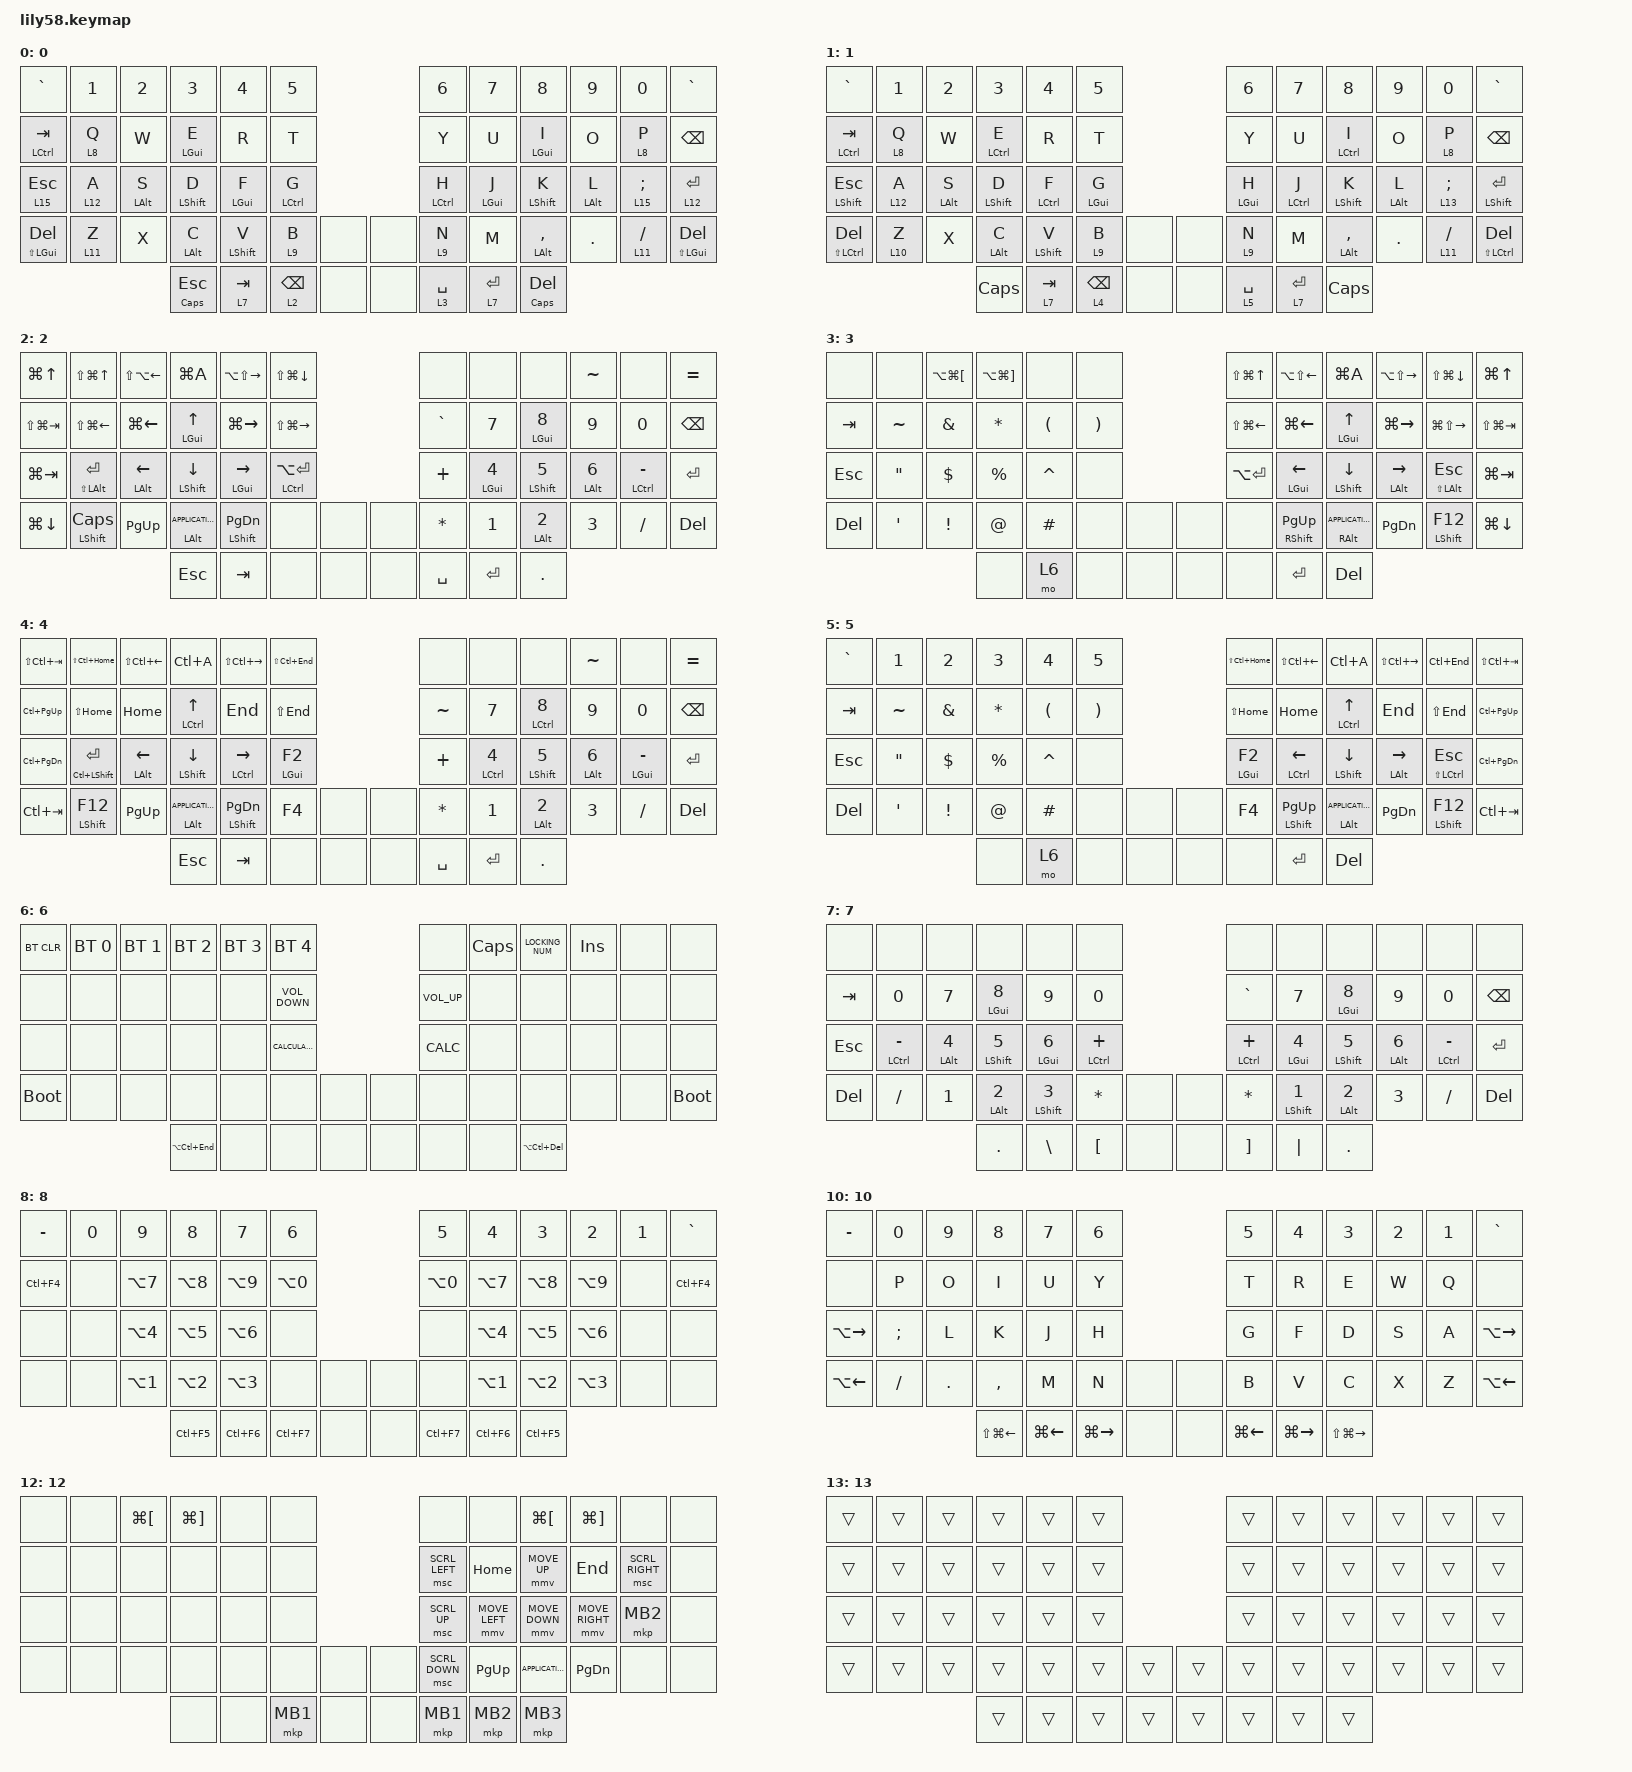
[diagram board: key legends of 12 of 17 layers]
/*
 * Copyright (c) 2020 The ZMK Contributors
 *
 * SPDX-License-Identifier: MIT
 */

#define ZMK_POINTING_DEFAULT_MOVE_VAL 900  // 기본 600
#define ZMK_POINTING_DEFAULT_SCRL_VAL 15    // 기본 10

#include <behaviors.dtsi>
#include <dt-bindings/zmk/bt.h>
#include <dt-bindings/zmk/keys.h>
#include <dt-bindings/zmk/pointing.h>

/ {
    combos {
        compatible = "zmk,combos";

        MOD_del {
            bindings = <&kp DELETE>;
            key-positions = <14 52>;
        };

        MOD_ent {
            bindings = <&kp ENTER>;
            key-positions = <15 52>;
            require-prior-idle-ms = <100>;
        };

        MOD_space {
            bindings = <&kp SPACE>;
            key-positions = <16 52>;
            require-prior-idle-ms = <100>;
        };

        MOD_BS {
            bindings = <&kp BACKSPACE>;
            key-positions = <55 19>;
            require-prior-idle-ms = <100>;
        };

        MOD_TA {
            bindings = <&kp TAB>;
            key-positions = <55 20>;
            require-prior-idle-ms = <100>;
        };

        MOD_esc {
            bindings = <&kp ESCAPE>;
            key-positions = <55 21>;
            require-prior-idle-ms = <100>;
        };

        Q_ {
            bindings = <&kp LS(Q)>;
            key-positions = <26 25>;
            layers = <0 1>;
        };

        W_ {
            bindings = <&kp LS(W)>;
            key-positions = <14 15>;
            layers = <0>;
        };

        E_ {
            bindings = <&kp LS(E)>;
            key-positions = <27 26>;
            layers = <0>;
        };

        R_ {
            bindings = <&kp LS(R)>;
            key-positions = <15 16>;
            layers = <0>;
        };

        T_ {
            bindings = <&kp LS(T)>;
            key-positions = <27 28>;
            layers = <0>;
        };

        P_ {
            bindings = <&kp LS(P)>;
            key-positions = <34 33>;
            layers = <0>;
        };

        B_ {
            bindings = <&kp B>;
            key-positions = <32 33>;
            layers = <0>;
        };

        paste0 {
            bindings = <&kp LG(V)>;
            key-positions = <52 28>;
            require-prior-idle-ms = <100>;
            layers = <0>;
        };

        copy0 {
            bindings = <&kp LG(C)>;
            key-positions = <27 52>;
            require-prior-idle-ms = <100>;
            layers = <0>;
        };

        cut0 {
            bindings = <&kp LG(X)>;
            key-positions = <26 52>;
            require-prior-idle-ms = <100>;
            layers = <0>;
        };

        AltTab0 {
            bindings = <&kp LG(TAB)>;
            key-positions = <25 52>;
            require-prior-idle-ms = <100>;
            layers = <0>;
        };

        paste1 {
            bindings = <&kp LC(V)>;
            key-positions = <52 28>;
            layers = <1>;
        };

        copy1 {
            bindings = <&kp LC(C)>;
            key-positions = <27 52>;
            layers = <1>;
        };

        cut1 {
            bindings = <&kp LC(X)>;
            key-positions = <26 52>;
            layers = <1>;
        };

        AltTab1 {
            bindings = <&kp LC(TAB)>;
            key-positions = <25 52>;
            layers = <1>;
        };

        Lan_LH0 {
            bindings = <&kp LC(SPACE)>;
            key-positions = <52 40>;
            layers = <0>;
        };

        Lan_RH0 {
            bindings = <&kp LC(SPACE)>;
            key-positions = <31 32>;
            layers = <0>;
        };

        Lan_LH1 {
            bindings = <&kp RALT>;
            key-positions = <52 40>;
            layers = <1>;
        };

        Lan_RH1 {
            bindings = <&kp RALT>;
            key-positions = <31 32>;
            layers = <1>;
        };

        Hanja_LH {
            bindings = <&kp RCTRL>;
            key-positions = <52 39>;
            layers = <0 1>;
        };

        Hanja_RH {
            bindings = <&kp RCTRL>;
            key-positions = <45 46>;
            layers = <0 1>;
        };

        question_LH {
            bindings = <&kp QUESTION>;
            key-positions = <37 38>;
            layers = <0 1>;
        };

        question_RH {
            bindings = <&kp QUESTION>;
            key-positions = <47 48>;
            layers = <0 1>;
        };

        click_L {
            bindings = <&mkp MB1>;
            key-positions = <29 52>;
            layers = <0 1>;
        };

        toWIN {
            bindings = <&to 0>;
            key-positions = <52 51 50>;
        };

        toMAC {
            bindings = <&mo 0>;
            key-positions = <55 56 57>;
        };
    };

    behaviors {
        hmMT: hmMT {
            compatible = "zmk,behavior-hold-tap";
            label = "HMMT";
            bindings = <&kp>, <&kp>;

            #binding-cells = <2>;
            tapping-term-ms = <250>;
            flavor = "tap-preferred";
        };

        hmLT: hmLT {
            compatible = "zmk,behavior-hold-tap";
            label = "HMLT";
            bindings = <&mo>, <&kp>;

            #binding-cells = <2>;
            tapping-term-ms = <250>;
            flavor = "tap-preferred";
        };
    };

    macros {
        new_macro0: new_macro0 {
            compatible = "zmk,behavior-macro";
            #binding-cells = <0>;
            bindings = <&kp LS(LG(RIGHT)) &kp LA(SPACE) &kp X>;
            label = "NEW_MACRO0";
        };

        new_macro1: new_macro1 {
            compatible = "zmk,behavior-macro";
            #binding-cells = <0>;
            bindings = <&kp LA(SPACE) &kp C>;
            label = "NEW_MACRO1";
        };

        new_macro2: new_macro2 {
            compatible = "zmk,behavior-macro";
            #binding-cells = <0>;
            bindings = <&kp LA(SPACE) &kp X>;
            label = "NEW_MACRO2";
        };

        new_macro3: new_macro3 {
            compatible = "zmk,behavior-macro";
            #binding-cells = <0>;
            bindings = <&kp LA(SPACE) &kp N>;
            label = "NEW_MACRO3";
        };

        new_macro4: new_macro4 {
            compatible = "zmk,behavior-macro";
            #binding-cells = <0>;
            bindings = <&kp LA(D) &kp LC(C) &kp LA(TAB)>;
            label = "NEW_MACRO4";
        };

        new_macro5: new_macro5 {
            compatible = "zmk,behavior-macro";
            #binding-cells = <0>;
            bindings = <&kp LA(D) &kp LC(V) &kp ENTER>;
            label = "NEW_MACRO5";
        };

        new_macro6: new_macro6 {
            compatible = "zmk,behavior-macro";
            #binding-cells = <0>;
            bindings = <&kp LEFT_PARENTHESIS &kp RIGHT_PARENTHESIS &kp LEFT_ARROW>;
            label = "NEW_MACRO6";
        };

        new_macro7: new_macro7 {
            compatible = "zmk,behavior-macro";
            #binding-cells = <0>;
            bindings = <&kp LESS_THAN &kp GREATER_THAN &kp LEFT_ARROW>;
            label = "NEW_MACRO7";
        };

        new_macro8: new_macro8 {
            compatible = "zmk,behavior-macro";
            #binding-cells = <0>;
            bindings = <&kp LEFT_BRACKET &kp RIGHT_BRACKET &kp LEFT_ARROW>;
            label = "NEW_MACRO8";
        };

        new_macro9: new_macro9 {
            compatible = "zmk,behavior-macro";
            #binding-cells = <0>;
            bindings = <&kp SPACE &kp SPACE &kp SPACE &kp SPACE>;
            label = "NEW_MACRO9";
        };

        new_macro10: new_macro10 {
            compatible = "zmk,behavior-macro";
            #binding-cells = <0>;
            bindings = <&kp N1 &kp N0>;
            label = "NEW_MACRO10";
        };

        new_macro11: new_macro11 {
            compatible = "zmk,behavior-macro";
            #binding-cells = <0>;
            bindings = <&kp N1 &kp N1>;
            label = "NEW_MACRO11";
        };

        new_macro12: new_macro12 {
            compatible = "zmk,behavior-macro";
            #binding-cells = <0>;
            bindings = <&kp N1 &kp N2>;
            label = "NEW_MACRO12";
        };

        new_macro13: new_macro13 {
            compatible = "zmk,behavior-macro";
            #binding-cells = <0>;
            bindings = <&kp N1 &kp NUMBER_3>;
            label = "NEW_MACRO13";
        };

        new_macro14: new_macro14 {
            compatible = "zmk,behavior-macro";
            #binding-cells = <0>;
            bindings = <&none>;
            label = "NEW_MACRO14";
        };

        new_macro15: new_macro15 {
            compatible = "zmk,behavior-macro";
            #binding-cells = <0>;
            bindings = <&none>;
            label = "NEW_MACRO15";
        };

        new_macro16: new_macro16 {
            compatible = "zmk,behavior-macro";
            #binding-cells = <0>;
            bindings =
                <&macro_press>,
                <&macro_tap>,
                <&macro_tap>,
                <&macro_tap>,
                <&macro_release>;

            label = "NEW_MACRO16";
        };

        new_macro17: new_macro17 {
            compatible = "zmk,behavior-macro";
            #binding-cells = <0>;
            bindings =
                <&macro_press>,
                <&macro_tap>,
                <&macro_tap>,
                <&macro_tap>,
                <&macro_release>;

            label = "NEW_MACRO17";
        };

        new_macro18: new_macro18 {
            compatible = "zmk,behavior-macro";
            #binding-cells = <0>;
            bindings = <&kp D &kp K &kp S &kp S &kp U &kp D &kp G &kp K &kp T &kp P &kp D &kp Y &kp TILDE>;
            label = "NEW_MACRO18";
        };

        new_macro19: new_macro19 {
            compatible = "zmk,behavior-macro";
            #binding-cells = <0>;
            bindings = <&kp R &kp K &kp A &kp T &kp K &kp G &kp K &kp Q &kp S &kp L &kp E &kp K &kp DOT>;
            label = "NEW_MACRO19";
        };

        new_macro20: new_macro20 {
            compatible = "zmk,behavior-macro";
            #binding-cells = <0>;
            bindings = <&none>;
            label = "NEW_MACRO20";
        };

        new_macro21: new_macro21 {
            compatible = "zmk,behavior-macro";
            #binding-cells = <0>;
            bindings = <&none>;
            label = "NEW_MACRO21";
        };

        new_macro22: new_macro22 {
            compatible = "zmk,behavior-macro";
            #binding-cells = <0>;
            bindings = <&none>;
            label = "NEW_MACRO22";
        };

        new_macro23: new_macro23 {
            compatible = "zmk,behavior-macro";
            #binding-cells = <0>;
            bindings = <&none>;
            label = "NEW_MACRO23";
        };

        new_macro31: new_macro31 {
            compatible = "zmk,behavior-macro";
            #binding-cells = <0>;
            bindings =
                <&macro_press>,
                <&macro_tap>,
                <&macro_tap>,
                <&macro_tap>,
                <&macro_release>;

            label = "NEW_MACRO31";
        };

        new_macro32: new_macro32 {
            compatible = "zmk,behavior-macro";
            #binding-cells = <0>;
            bindings =
                <&macro_press>,
                <&macro_tap>,
                <&macro_tap>,
                <&macro_tap>,
                <&macro_release>;

            label = "NEW_MACRO32";
        };

        new_macro33: new_macro33 {
            compatible = "zmk,behavior-macro";
            #binding-cells = <0>;
            bindings =
                <&macro_press>,
                <&macro_tap>,
                <&macro_tap>,
                <&macro_tap>,
                <&macro_release>;

            label = "NEW_MACRO33";
        };

        new_macro34: new_macro34 {
            compatible = "zmk,behavior-macro";
            #binding-cells = <0>;
            bindings =
                <&macro_press>,
                <&macro_tap>,
                <&macro_tap>,
                <&macro_tap>,
                <&macro_release>;

            label = "NEW_MACRO34";
        };

        new_macro35: new_macro35 {
            compatible = "zmk,behavior-macro";
            #binding-cells = <0>;
            bindings =
                <&macro_press>,
                <&macro_tap>,
                <&macro_tap>,
                <&macro_tap>,
                <&macro_release>;

            label = "NEW_MACRO35";
        };

        new_macro36: new_macro36 {
            compatible = "zmk,behavior-macro";
            #binding-cells = <0>;
            bindings =
                <&macro_press>,
                <&macro_tap>,
                <&macro_tap>,
                <&macro_tap>,
                <&macro_release>;

            label = "NEW_MACRO36";
        };

        new_macro37: new_macro37 {
            compatible = "zmk,behavior-macro";
            #binding-cells = <0>;
            bindings =
                <&macro_press>,
                <&macro_tap>,
                <&macro_tap>,
                <&macro_tap>,
                <&macro_release>;

            label = "NEW_MACRO37";
        };

        new_macro38: new_macro38 {
            compatible = "zmk,behavior-macro";
            #binding-cells = <0>;
            bindings =
                <&macro_press>,
                <&macro_tap>,
                <&macro_tap>,
                <&macro_tap>,
                <&macro_release>;

            label = "NEW_MACRO38";
        };

        new_macro39: new_macro39 {
            compatible = "zmk,behavior-macro";
            #binding-cells = <0>;
            bindings =
                <&macro_press>,
                <&macro_tap>,
                <&macro_tap>,
                <&macro_tap>,
                <&macro_release>;

            label = "NEW_MACRO39";
        };

        new_macro40: new_macro40 {
            compatible = "zmk,behavior-macro";
            #binding-cells = <0>;
            bindings =
                <&macro_press>,
                <&macro_tap>,
                <&macro_tap>,
                <&macro_tap>,
                <&macro_release>;

            label = "NEW_MACRO40";
        };

        new_macro41: new_macro41 {
            compatible = "zmk,behavior-macro";
            #binding-cells = <0>;
            bindings =
                <&macro_press>,
                <&macro_tap>,
                <&macro_tap>,
                <&macro_tap>,
                <&macro_release>;

            label = "NEW_MACRO41";
        };

        new_macro42: new_macro42 {
            compatible = "zmk,behavior-macro";
            #binding-cells = <0>;
            bindings =
                <&macro_press>,
                <&macro_tap>,
                <&macro_tap>,
                <&macro_tap>,
                <&macro_release>;

            label = "NEW_MACRO42";
        };

        new_macro43: new_macro43 {
            compatible = "zmk,behavior-macro";
            #binding-cells = <0>;
            bindings =
                <&macro_press>,
                <&macro_tap>,
                <&macro_tap>,
                <&macro_tap>,
                <&macro_release>;

            label = "NEW_MACRO43";
        };

        new_macro44: new_macro44 {
            compatible = "zmk,behavior-macro";
            #binding-cells = <0>;
            bindings =
                <&macro_press>,
                <&macro_tap>,
                <&macro_tap>,
                <&macro_tap>,
                <&macro_release>;

            label = "NEW_MACRO44";
        };

        new_macro45: new_macro45 {
            compatible = "zmk,behavior-macro";
            #binding-cells = <0>;
            bindings =
                <&macro_press>,
                <&macro_tap>,
                <&macro_tap>,
                <&macro_tap>,
                <&macro_release>;

            label = "NEW_MACRO45";
        };

        new_macro46: new_macro46 {
            compatible = "zmk,behavior-macro";
            #binding-cells = <0>;
            bindings =
                <&macro_press>,
                <&macro_tap>,
                <&macro_tap>,
                <&macro_tap>,
                <&macro_release>;

            label = "NEW_MACRO46";
        };

        new_macro47: new_macro47 {
            compatible = "zmk,behavior-macro";
            #binding-cells = <0>;
            bindings =
                <&macro_press>,
                <&macro_tap>,
                <&macro_tap>,
                <&macro_tap>,
                <&macro_release>;

            label = "NEW_MACRO47";
        };

        new_macro48: new_macro48 {
            compatible = "zmk,behavior-macro";
            #binding-cells = <0>;
            bindings =
                <&macro_press>,
                <&macro_tap>,
                <&macro_tap>,
                <&macro_tap>,
                <&macro_release>;

            label = "NEW_MACRO48";
        };

        new_macro49: new_macro49 {
            compatible = "zmk,behavior-macro";
            #binding-cells = <0>;
            bindings =
                <&macro_press>,
                <&macro_tap>,
                <&macro_tap>,
                <&macro_tap>,
                <&macro_release>;

            label = "NEW_MACRO49";
        };

        new_macro50: new_macro50 {
            compatible = "zmk,behavior-macro";
            #binding-cells = <0>;
            bindings =
                <&macro_press>,
                <&macro_tap>,
                <&macro_tap>,
                <&macro_tap>,
                <&macro_release>;

            label = "NEW_MACRO50";
        };

        new_macro51: new_macro51 {
            compatible = "zmk,behavior-macro";
            #binding-cells = <0>;
            bindings =
                <&macro_press>,
                <&macro_tap>,
                <&macro_tap>,
                <&macro_tap>,
                <&macro_release>;

            label = "NEW_MACRO51";
        };

        new_macro52: new_macro52 {
            compatible = "zmk,behavior-macro";
            #binding-cells = <0>;
            bindings =
                <&macro_press>,
                <&macro_tap>,
                <&macro_tap>,
                <&macro_tap>,
                <&macro_release>;

            label = "NEW_MACRO52";
        };

        new_macro53: new_macro53 {
            compatible = "zmk,behavior-macro";
            #binding-cells = <0>;
            bindings =
                <&macro_press>,
                <&macro_tap>,
                <&macro_tap>,
                <&macro_tap>,
                <&macro_release>;

            label = "NEW_MACRO53";
        };

        new_macro54: new_macro54 {
            compatible = "zmk,behavior-macro";
            #binding-cells = <0>;
            bindings =
                <&macro_press>,
                <&macro_tap>,
                <&macro_tap>,
                <&macro_tap>,
                <&macro_release>;

            label = "NEW_MACRO54";
        };

        new_macro55: new_macro55 {
            compatible = "zmk,behavior-macro";
            #binding-cells = <0>;
            bindings =
                <&macro_press>,
                <&macro_tap>,
                <&macro_tap>,
                <&macro_tap>,
                <&macro_release>;

            label = "NEW_MACRO55";
        };

        new_macro56: new_macro56 {
            compatible = "zmk,behavior-macro";
            #binding-cells = <0>;
            bindings =
                <&macro_press>,
                <&macro_tap>,
                <&macro_tap>,
                <&macro_tap>,
                <&macro_release>;

            label = "NEW_MACRO56";
        };

        new_macro57: new_macro57 {
            compatible = "zmk,behavior-macro";
            #binding-cells = <0>;
            bindings =
                <&macro_press>,
                <&macro_tap>,
                <&macro_tap>,
                <&macro_tap>,
                <&macro_release>;

            label = "NEW_MACRO57";
        };

        new_macro58: new_macro58 {
            compatible = "zmk,behavior-macro";
            #binding-cells = <0>;
            bindings =
                <&macro_press>,
                <&macro_tap>,
                <&macro_tap>,
                <&macro_tap>,
                <&macro_release>;

            label = "NEW_MACRO58";
        };

        new_macro59: new_macro59 {
            compatible = "zmk,behavior-macro";
            #binding-cells = <0>;
            bindings =
                <&macro_press>,
                <&macro_tap>,
                <&macro_tap>,
                <&macro_tap>,
                <&macro_release>;

            label = "NEW_MACRO59";
        };

        new_macro60: new_macro60 {
            compatible = "zmk,behavior-macro";
            #binding-cells = <0>;
            bindings =
                <&macro_press>,
                <&macro_tap>,
                <&macro_tap>,
                <&macro_tap>,
                <&macro_release>;

            label = "NEW_MACRO60";
        };

        new_macro61: new_macro61 {
            compatible = "zmk,behavior-macro";
            #binding-cells = <0>;
            bindings =
                <&macro_press>,
                <&macro_tap>,
                <&macro_tap>,
                <&macro_tap>,
                <&macro_release>;

            label = "NEW_MACRO61";
        };

        new_macro62: new_macro62 {
            compatible = "zmk,behavior-macro";
            #binding-cells = <0>;
            bindings =
                <&macro_press>,
                <&macro_tap>,
                <&macro_tap>,
                <&macro_tap>,
                <&macro_release>;

            label = "NEW_MACRO62";
        };

        new_macro63: new_macro63 {
            compatible = "zmk,behavior-macro";
            #binding-cells = <0>;
            bindings =
                <&macro_press>,
                <&macro_tap>,
                <&macro_tap>,
                <&macro_tap>,
                <&macro_release>;

            label = "NEW_MACRO63";
        };

        new_macro64: new_macro64 {
            compatible = "zmk,behavior-macro";
            #binding-cells = <0>;
            bindings =
                <&macro_press>,
                <&macro_tap>,
                <&macro_tap>,
                <&macro_tap>,
                <&macro_release>;

            label = "NEW_MACRO64";
        };

        new_macro65: new_macro65 {
            compatible = "zmk,behavior-macro";
            #binding-cells = <0>;
            bindings =
                <&macro_press>,
                <&macro_tap>,
                <&macro_tap>,
                <&macro_tap>,
                <&macro_release>;

            label = "NEW_MACRO65";
        };

        new_macro66: new_macro66 {
            compatible = "zmk,behavior-macro";
            #binding-cells = <0>;
            bindings =
                <&macro_press>,
                <&macro_tap>,
                <&macro_tap>,
                <&macro_tap>,
                <&macro_release>;

            label = "NEW_MACRO66";
        };

        new_macro67: new_macro67 {
            compatible = "zmk,behavior-macro";
            #binding-cells = <0>;
            bindings =
                <&macro_press>,
                <&macro_tap>,
                <&macro_tap>,
                <&macro_tap>,
                <&macro_release>;

            label = "NEW_MACRO67";
        };

        new_macro68: new_macro68 {
            compatible = "zmk,behavior-macro";
            #binding-cells = <0>;
            bindings =
                <&macro_press>,
                <&macro_tap>,
                <&macro_tap>,
                <&macro_tap>,
                <&macro_release>;

            label = "NEW_MACRO68";
        };

        new_macro69: new_macro69 {
            compatible = "zmk,behavior-macro";
            #binding-cells = <0>;
            bindings =
                <&macro_press>,
                <&macro_tap>,
                <&macro_tap>,
                <&macro_tap>,
                <&macro_release>;

            label = "NEW_MACRO69";
        };

        new_macro70: new_macro70 {
            compatible = "zmk,behavior-macro";
            #binding-cells = <0>;
            bindings =
                <&macro_press>,
                <&macro_tap>,
                <&macro_tap>,
                <&macro_tap>,
                <&macro_release>;

            label = "NEW_MACRO70";
        };

        new_macro71: new_macro71 {
            compatible = "zmk,behavior-macro";
            #binding-cells = <0>;
            bindings =
                <&macro_press>,
                <&macro_tap>,
                <&macro_tap>,
                <&macro_tap>,
                <&macro_release>;

            label = "NEW_MACRO71";
        };

        new_macro72: new_macro72 {
            compatible = "zmk,behavior-macro";
            #binding-cells = <0>;
            bindings =
                <&macro_press>,
                <&macro_tap>,
                <&macro_tap>,
                <&macro_tap>,
                <&macro_release>;

            label = "NEW_MACRO72";
        };

        new_macro73: new_macro73 {
            compatible = "zmk,behavior-macro";
            #binding-cells = <0>;
            bindings =
                <&macro_press>,
                <&macro_tap>,
                <&macro_tap>,
                <&macro_tap>,
                <&macro_release>;

            label = "NEW_MACRO73";
        };

        new_macro74: new_macro74 {
            compatible = "zmk,behavior-macro";
            #binding-cells = <0>;
            bindings =
                <&macro_press>,
                <&macro_tap>,
                <&macro_tap>,
                <&macro_tap>,
                <&macro_release>;

            label = "NEW_MACRO74";
        };

        new_macro75: new_macro75 {
            compatible = "zmk,behavior-macro";
            #binding-cells = <0>;
            bindings =
                <&macro_press>,
                <&macro_tap>,
                <&macro_tap>,
                <&macro_tap>,
                <&macro_release>;

            label = "NEW_MACRO75";
        };

        new_macro76: new_macro76 {
            compatible = "zmk,behavior-macro";
            #binding-cells = <0>;
            bindings =
                <&macro_press>,
                <&macro_tap>,
                <&macro_tap>,
                <&macro_tap>,
                <&macro_release>;

            label = "NEW_MACRO76";
        };

        new_macro77: new_macro77 {
            compatible = "zmk,behavior-macro";
            #binding-cells = <0>;
            bindings =
                <&macro_press>,
                <&macro_tap>,
                <&macro_tap>,
                <&macro_tap>,
                <&macro_release>;

            label = "NEW_MACRO77";
        };

        new_macro78: new_macro78 {
            compatible = "zmk,behavior-macro";
            #binding-cells = <0>;
            bindings =
                <&macro_press>,
                <&macro_tap>,
                <&macro_tap>,
                <&macro_tap>,
                <&macro_release>;

            label = "NEW_MACRO78";
        };

        new_macro79: new_macro79 {
            compatible = "zmk,behavior-macro";
            #binding-cells = <0>;
            bindings =
                <&macro_press>,
                <&macro_tap>,
                <&macro_tap>,
                <&macro_tap>,
                <&macro_release>;

            label = "NEW_MACRO79";
        };

        new_macro80: new_macro80 {
            compatible = "zmk,behavior-macro";
            #binding-cells = <0>;
            bindings =
                <&macro_press>,
                <&macro_tap>,
                <&macro_tap>,
                <&macro_tap>,
                <&macro_release>;

            label = "NEW_MACRO80";
        };

        new_macro81: new_macro81 {
            compatible = "zmk,behavior-macro";
            #binding-cells = <0>;
            bindings =
                <&macro_press>,
                <&macro_tap>,
                <&macro_tap>,
                <&macro_tap>,
                <&macro_release>;

            label = "NEW_MACRO81";
        };

        new_macro82: new_macro82 {
            compatible = "zmk,behavior-macro";
            #binding-cells = <0>;
            bindings =
                <&macro_press>,
                <&macro_tap>,
                <&macro_tap>,
                <&macro_tap>,
                <&macro_release>;

            label = "NEW_MACRO82";
        };

        new_macro100: new_macro100 {
            compatible = "zmk,behavior-macro";
            #binding-cells = <0>;
            bindings = <&kp SEMI &kp T &kp J &kp P &kp J>;
            label = "NEW_MACRO100";
        };

        new_macro101: new_macro101 {
            compatible = "zmk,behavior-macro";
            #binding-cells = <0>;
            bindings = <&kp SEMI &kp S &kp D &kp W &kp T>;
            label = "NEW_MACRO101";
        };

        new_macro102: new_macro102 {
            compatible = "zmk,behavior-macro";
            #binding-cells = <0>;
            bindings = <&kp SEMI &kp W &kp T &kp W &kp F>;
            label = "NEW_MACRO102";
        };

        new_macro103: new_macro103 {
            compatible = "zmk,behavior-macro";
            #binding-cells = <0>;
            bindings = <&kp SEMI &kp P &kp T>;
            label = "NEW_MACRO103";
        };

        new_macro104: new_macro104 {
            compatible = "zmk,behavior-macro";
            #binding-cells = <0>;
            bindings = <&kp SEMI &kp D &kp D &kp W &kp T>;
            label = "NEW_MACRO104";
        };

        new_macro105: new_macro105 {
            compatible = "zmk,behavior-macro";
            #binding-cells = <0>;
            bindings = <&kp SEMI &kp Q &kp A &kp W &kp F>;
            label = "NEW_MACRO105";
        };
    };

    keymap {
        compatible = "zmk,keymap";

        layer_0 {
            display-name = "0";
            bindings = <
&kp GRAVE             &kp N1    &kp N2        &kp N3           &kp N4              &kp N5                           &kp N6         &kp N7        &kp N8            &kp N9        &kp N0            &kp GRAVE
&mt LEFT_CONTROL TAB  &lt 8 Q   &kp W         &hmMT LGUI E     &kp R               &kp T                            &kp Y          &kp U         &hmMT LGUI I      &kp O         &lt 8 P           &kp BACKSPACE
&lt 15 ESCAPE         &lt 12 A  &hmMT LALT S  &hmMT LSHIFT D   &hmMT LGUI F        &hmMT LCTRL G                    &hmMT LCTRL H  &hmMT LGUI J  &hmMT LSHIFT K    &hmMT LALT L  &lt 15 SEMICOLON  &lt 12 ENTER
&mt LS(LGUI) DELETE   &lt 11 Z  &kp X         &hmMT LALT C     &hmMT LEFT_SHIFT V  &lt 9 B          &none    &none  &lt 9 N        &kp M         &hmMT LALT COMMA  &kp DOT       &lt 11 SLASH      &mt LS(LGUI) DELETE
                                              &mt CAPS ESCAPE  &lt 7 TAB           &lt 2 BACKSPACE  &none    &none  &lt 3 SPACE    &lt 7 ENTER   &mt CAPS DELETE
            >;
        };

        layer_1 {
            display-name = "1";
            bindings = <
&kp GRAVE             &kp N1    &kp N2        &kp N3          &kp N4              &kp N5                           &kp N6        &kp N7         &kp N8            &kp N9        &kp N0            &kp GRAVE
&mt LEFT_CONTROL TAB  &lt 8 Q   &kp W         &hmMT LCTRL E   &kp R               &kp T                            &kp Y         &kp U          &hmMT LCTRL I     &kp O         &lt 8 P           &kp BACKSPACE
&mt LSHIFT ESCAPE     &lt 12 A  &hmMT LALT S  &hmMT LSHIFT D  &hmMT LCTRL F       &hmMT LGUI G                     &hmMT LGUI H  &hmMT LCTRL J  &hmMT LSHIFT K    &hmMT LALT L  &lt 13 SEMICOLON  &mt LSHIFT ENTER
&mt LS(LCTRL) DELETE  &lt 10 Z  &kp X         &hmMT LALT C    &hmMT LEFT_SHIFT V  &lt 9 B          &none    &none  &lt 9 N       &kp M          &hmMT LALT COMMA  &kp DOT       &lt 11 SLASH      &mt LS(LCTRL) DELETE
                                              &kp CAPS        &lt 7 TAB           &lt 4 BACKSPACE  &none    &none  &lt 5 SPACE   &lt 7 ENTER    &kp CAPS
            >;
        };

        layer_2 {
            bindings = <
&kp LG(UP)       &kp LS(LG(UP))            &kp LS(LA(LEFT))     &kp LG(A)                 &kp LA(LS(RIGHT))       &kp LS(LG(DOWN))                       &none         &none          &none              &kp TILDE      &none              &kp EQUAL
&kp LS(LG(TAB))  &kp LS(LG(LEFT))          &kp LG(LEFT)         &hmMT LGUI UP             &kp LG(RIGHT)           &kp LS(LG(RIGHT))                      &kp GRAVE     &kp N7         &hmMT LGUI N8      &kp N9         &kp N0             &kp BACKSPACE
&kp LG(TAB)      &hmMT LS(LEFT_ALT) ENTER  &hmMT LEFT_ALT LEFT  &hmMT LSHIFT DOWN         &hmMT LGUI RIGHT        &hmMT LCTRL LA(ENTER)                  &kp PLUS      &hmMT LGUI N4  &hmMT LSHFT N5     &hmMT LALT N6  &hmMT LCTRL MINUS  &kp ENTER
&kp LG(DOWN)     &hmMT LSHIFT CAPS         &kp PAGE_UP          &hmMT LALT K_APPLICATION  &hmMT LSHIFT PAGE_DOWN  &none                  &none    &none  &kp ASTERISK  &kp N1         &hmMT LEFT_ALT N2  &kp N3         &kp SLASH          &kp DELETE
                                                                &kp ESCAPE                &kp TAB                 &none                  &none    &none  &kp SPACE     &kp ENTER      &kp DOT
            >;

            label = "2";
        };

        layer_3 {
            bindings = <
&none       &none              &kp LA(LG(LEFT_BRACKET))  &kp LA(LG(RIGHT_BRACKET))  &none                 &none                                  &kp LS(LG(UP_ARROW))  &kp LA(LS(LEFT))      &kp LG(A)                      &kp LA(LS(RIGHT))     &kp LS(LG(DOWN))           &kp LG(UP)
&kp TAB     &kp TILDE          &kp AMPERSAND             &kp ASTERISK               &kp LEFT_PARENTHESIS  &kp RIGHT_PARENTHESIS                  &kp LS(LG(LEFT))      &kp LG(LEFT)          &hmMT LGUI UP                  &kp LG(RIGHT)         &kp LG(LS(RIGHT))          &kp LS(LG(TAB))
&kp ESCAPE  &kp DOUBLE_QUOTES  &kp DOLLAR                &kp PERCENT                &kp CARET             &none                                  &kp LA(ENTER)         &hmMT LGUI LEFT       &hmMT LSHIFT DOWN              &hmMT LEFT_ALT RIGHT  &hmMT LS(LEFT_ALT) ESCAPE  &kp LG(TAB)
&kp DELETE  &kp SQT            &kp EXCLAMATION           &kp AT_SIGN                &kp HASH              &none                  &none    &none  &none                 &hmMT RSHIFT PAGE_UP  &hmMT RIGHT_ALT K_APPLICATION  &kp PAGE_DOWN         &hmMT LSHIFT F12           &kp LG(DOWN)
                                                         &none                      &mo 6                 &none                  &none    &none  &none                 &kp ENTER             &kp DELETE
            >;

            label = "3";
        };

        layer_4 {
            bindings = <
&kp LS(LC(TAB))    &kp LS(LC(HOME))        &kp LS(LC(LEFT))  &kp LC(A)                 &kp LS(LC(RIGHT))       &kp LS(LC(END))                  &none         &none           &none            &kp TILDE      &none             &kp EQUAL
&kp LC(PAGE_UP)    &kp LS(HOME)            &kp HOME          &hmMT LCTRL UP            &kp END                 &kp LS(END)                      &kp TILDE     &kp N7          &hmMT LCTRL N8   &kp N9         &kp N0            &kp BACKSPACE
&kp LC(PAGE_DOWN)  &hmMT LC(LSHIFT) ENTER  &hmMT LALT LEFT   &hmMT LSHFT DOWN          &hmMT LCTRL RIGHT       &hmMT LGUI F2                    &kp PLUS      &hmMT LCTRL N4  &hmMT LSHIFT N5  &hmMT LALT N6  &hmMT LGUI MINUS  &kp ENTER
&kp LC(TAB)        &hmMT LSHIFT F12        &kp PAGE_UP       &hmMT LALT K_APPLICATION  &hmMT LSHIFT PAGE_DOWN  &kp F4           &none    &none  &kp ASTERISK  &kp N1          &hmMT LALT N2    &kp N3         &kp SLASH         &kp DELETE
                                                             &kp ESCAPE                &kp TAB                 &none            &none    &none  &kp SPACE     &kp ENTER       &kp DOT
            >;

            label = "4";
        };

        layer_5 {
            display-name = "5";
            bindings = <
&kp GRAVE   &kp N1             &kp N2           &kp N3        &kp N4                &kp N5                                 &kp LS(LC(HOME))  &kp LS(LC(LEFT))          &kp LC(A)                 &kp LS(LC(RIGHT))  &kp LC(END)             &kp LS(LC(TAB))
&kp TAB     &kp TILDE          &kp AMPERSAND    &kp ASTERISK  &kp LEFT_PARENTHESIS  &kp RIGHT_PARENTHESIS                  &kp LS(HOME)      &kp HOME                  &hmMT LCTRL UP            &kp END            &kp LS(END)             &kp LC(PAGE_UP)
&kp ESCAPE  &kp DOUBLE_QUOTES  &kp DOLLAR       &kp PERCENT   &kp CARET             &none                                  &hmMT LGUI F2     &hmMT LCTRL LEFT          &hmMT LSHIFT DOWN         &hmMT LALT RIGHT   &hmMT LS(LCTRL) ESCAPE  &kp LC(PAGE_DOWN)
&kp DELETE  &kp SQT            &kp EXCLAMATION  &kp AT_SIGN   &kp HASH              &none                  &none    &none  &kp F4            &hmMT LEFT_SHIFT PAGE_UP  &hmMT LALT K_APPLICATION  &kp PAGE_DOWN      &hmMT LSHIFT F12        &kp LC(TAB)
                                                &none         &mo 6                 &none                  &none    &none  &none             &kp ENTER                 &kp DELETE
            >;
        };

        layer_6 {
            display-name = "6";
            bindings = <
&bt BT_CLR   &bt BT_SEL 0  &bt BT_SEL 1  &bt BT_SEL 2     &bt BT_SEL 3  &bt BT_SEL 4                       &none            &kp CAPSLOCK  &kp LOCKING_NUM  &kp INSERT  &none  &none
&none        &none         &none         &none            &none         &kp C_VOLUME_DOWN                  &kp C_VOLUME_UP  &none         &none            &none       &none  &none
&none        &none         &none         &none            &none         &kp K_CALCULATOR                   &kp K_CALC       &none         &none            &none       &none  &none
&bootloader  &none         &none         &none            &none         &none              &none    &none  &none            &none         &none            &none       &none  &bootloader
                                         &kp LA(LC(END))  &none         &none              &none    &none  &none            &none         &kp LA(LC(DEL))
            >;
        };

        layer_7 {
            bindings = <
&none    &none              &none              &none            &none            &none                             &none             &none            &none            &none          &none              &none
&kp TAB  &kp N0             &kp N7             &hmMT LGUI N8    &kp N9           &kp N0                            &kp GRAVE         &kp N7           &hmMT LGUI N8    &kp N9         &kp N0             &kp BSPC
&kp ESC  &hmMT LCTRL MINUS  &hmMT LEFT_ALT N4  &hmMT LSHIFT N5  &hmMT LGUI N6    &hmMT LCTRL PLUS                  &hmMT LCTRL PLUS  &hmMT LGUI N4    &hmMT LSHIFT N5  &hmMT LALT N6  &hmMT LCTRL MINUS  &kp RET
&kp DEL  &kp FSLH           &kp N1             &hmMT LALT N2    &hmMT LSHIFT N3  &kp ASTERISK      &none    &none  &kp ASTERISK      &hmMT LSHIFT N1  &hmMT LALT N2    &kp N3         &kp FSLH           &kp DEL
                                               &kp DOT          &kp BSLH         &kp LBKT          &none    &none  &kp RBKT          &kp PIPE         &kp DOT
            >;

            label = "7";
        };

        layer_8 {
            bindings = <
&kp MINUS   &kp N0  &kp N9      &kp N8      &kp N7      &kp NUMBER_6                  &kp N5      &kp N4      &kp N3      &kp N2      &kp N1  &kp GRAVE
&kp LC(F4)  &none   &kp LA(N7)  &kp LA(N8)  &kp LA(N9)  &kp LA(N0)                    &kp LA(N0)  &kp LA(N7)  &kp LA(N8)  &kp LA(N9)  &none   &kp LC(F4)
&none       &none   &kp LA(N4)  &kp LA(N5)  &kp LA(N6)  &none                         &none       &kp LA(N4)  &kp LA(N5)  &kp LA(N6)  &none   &none
&none       &none   &kp LA(N1)  &kp LA(N2)  &kp LA(N3)  &none         &none    &none  &none       &kp LA(N1)  &kp LA(N2)  &kp LA(N3)  &none   &none
                                &kp LC(F5)  &kp LC(F6)  &kp LC(F7)    &none    &none  &kp LC(F7)  &kp LC(F6)  &kp LC(F5)
            >;

            label = "8";
        };

        layer_9 {
            bindings = <
&none                    &none                    &none                   &kp LS(LA(LC(LG(F19))))  &none                   &none                                    &kp F19  &none   &none   &none   &none    &none
&kp LS(LA(LC(LG(F13))))  &kp LS(LA(LC(LG(F16))))  &kp LS(LA(LC(LG(F7))))  &kp LS(LA(LC(LG(F8))))   &kp LS(LA(LC(LG(F9))))  &kp LS(LA(LC(LG(F8))))                   &kp F16  &kp F7  &kp F8  &kp F9  &kp F10  &kp F13
&kp LS(LA(LC(LG(F14))))  &kp LS(LA(LC(LG(F17))))  &kp LS(LA(LC(LG(F4))))  &kp LS(LA(LC(LG(F5))))   &kp LS(LA(LC(LG(F6))))  &kp LS(LA(LC(LG(F5))))                   &kp F17  &kp F4  &kp F5  &kp F6  &kp F11  &kp F14
&kp LS(LA(LC(LG(F15))))  &kp LS(LA(LC(LG(F18))))  &kp LS(LA(LC(LG(F1))))  &kp LS(LA(LC(LG(F2))))   &kp LS(LA(LC(LG(F3))))  &kp LS(LA(LC(LG(F12))))  &none    &none  &kp F18  &kp F1  &kp F2  &kp F3  &kp F12  &kp F15
                                                                          &kp LS(LA(LC(LG(N))))    &kp LS(LA(LC(LG(X))))   &kp LS(LA(LC(LG(Q))))    &none    &none  &none    &none   &none
            >;

            label = "9";
        };

        layer_10 {
            label = "10";
            bindings = <
&kp MINUS      &kp N0         &kp N9      &kp N8            &kp N7        &kp N6                         &kp N5        &kp N4         &kp N3             &kp N2  &kp N1  &kp GRAVE
&none          &kp P          &kp O       &kp I             &kp U         &kp Y                          &kp T         &kp R          &kp E              &kp W   &kp Q   &none
&kp LA(RIGHT)  &kp SEMICOLON  &kp L       &kp K             &kp J         &kp H                          &kp G         &kp F          &kp D              &kp S   &kp A   &kp LA(RIGHT)
&kp LA(LEFT)   &kp SLASH      &kp PERIOD  &kp COMMA         &kp M         &kp N          &none    &none  &kp B         &kp V          &kp C              &kp X   &kp Z   &kp LA(LEFT)
                                          &kp LS(LG(LEFT))  &kp LG(LEFT)  &kp LG(RIGHT)  &none    &none  &kp LG(LEFT)  &kp LG(RIGHT)  &kp LS(LG(RIGHT))
            >;
        };

        layer_11 {
            bindings = <
&kp MINUS     &kp N0         &kp N9      &kp N8                   &kp N7                  &kp N6                                  &kp N5                  &kp N4                  &kp N3                   &kp N2  &kp N1  &kp GRAVE
&none         &kp P          &kp O       &kp I                    &kp U                   &kp Y                                   &kp T                   &kp R                   &kp E                    &kp W   &kp Q   &none
&kp LG(RBKT)  &kp SEMICOLON  &kp L       &kp K                    &kp J                   &kp H                                   &kp G                   &kp F                   &kp D                    &kp S   &kp A   &kp LG(RBKT)
&kp LG(LBKT)  &kp SLASH      &kp PERIOD  &kp COMMA                &kp M                   &kp N                   &none    &none  &kp B                   &kp V                   &kp C                    &kp X   &kp Z   &kp LG(LBKT)
                                         &kp LS(LA(LC(LG(F19))))  &kp LS(LA(LC(LG(F4))))  &kp LS(LA(LC(LG(F6))))  &none    &none  &kp LS(LA(LC(LG(F4))))  &kp LS(LA(LC(LG(F6))))  &kp LS(LA(LC(LG(F22))))
            >;

            label = "11";
        };

        layer_12 {
            bindings = <
&none  &none  &kp LG(LBKT)  &kp LG(RBKT)  &none  &none                     &none           &none           &kp LG(LBKT)       &kp LG(RBKT)     &none            &none
&none  &none  &none         &none         &none  &none                     &msc SCRL_LEFT  &kp HOME        &mmv MOVE_UP       &kp END          &msc SCRL_RIGHT  &none
&none  &none  &none         &none         &none  &none                     &msc SCRL_UP    &mmv MOVE_LEFT  &mmv MOVE_DOWN     &mmv MOVE_RIGHT  &mkp MB2         &none
&none  &none  &none         &none         &none  &none     &none    &none  &msc SCRL_DOWN  &kp PAGE_UP     &kp K_APPLICATION  &kp PAGE_DOWN    &none            &none
                            &none         &none  &mkp MB1  &none    &none  &mkp MB1        &mkp MB2        &mkp MB3
            >;

            label = "12";
        };

        layer_13 {
            bindings = <
&trans  &trans  &trans  &trans  &trans  &trans                    &trans  &trans  &trans  &trans  &trans  &trans
&trans  &trans  &trans  &trans  &trans  &trans                    &trans  &trans  &trans  &trans  &trans  &trans
&trans  &trans  &trans  &trans  &trans  &trans                    &trans  &trans  &trans  &trans  &trans  &trans
&trans  &trans  &trans  &trans  &trans  &trans  &trans    &trans  &trans  &trans  &trans  &trans  &trans  &trans
                        &trans  &trans  &trans  &trans    &trans  &trans  &trans  &trans
            >;

            label = "13";
        };

        layer_14 {
            bindings = <
&trans  &trans  &trans  &trans  &trans  &trans                    &trans  &trans  &trans  &trans  &trans  &trans
&trans  &trans  &trans  &trans  &trans  &trans                    &trans  &trans  &trans  &trans  &trans  &trans
&trans  &trans  &trans  &trans  &trans  &trans                    &trans  &trans  &trans  &trans  &trans  &trans
&trans  &trans  &trans  &trans  &trans  &trans  &trans    &trans  &trans  &trans  &trans  &trans  &trans  &trans
                        &trans  &trans  &trans  &trans    &trans  &trans  &trans  &trans
            >;

            label = "14";
        };

        layer_15 {
            bindings = <
&kp GRAVE  &kp N1     &kp N2     &kp N3     &kp N4     &kp N5                            &kp N6            &kp N7     &kp N8     &kp N9     &kp N0     &kp MINUS
&kp TAB    &kp LA(Q)  &kp LA(W)  &kp LA(E)  &kp LA(R)  &kp LA(T)                         &kp LA(Y)         &kp LA(U)  &kp LA(I)  &kp LA(O)  &kp LA(P)  &kp BSPC
&kp ESC    &kp LA(A)  &kp LA(S)  &kp LA(D)  &kp LA(F)  &kp LA(G)                         &kp LA(H)         &kp LA(J)  &kp LA(K)  &kp LA(L)  &none      &kp RET
&kp DEL    &kp LA(Z)  &kp LA(X)  &kp LA(C)  &kp LA(V)  &kp LA(B)         &none    &none  &kp LA(N)         &kp LA(M)  &kp COMMA  &kp DOT    &kp FSLH   &kp DEL
                                 &kp ESC    &kp TAB    &lt 16 BACKSPACE  &none    &none  &mt LSHIFT SPACE  &kp ENTER  &kp DEL
            >;

            label = "15";
        };

        layer_16 {
            label = "16";
            bindings = <
&kp GRAVE  &kp N1         &kp N2      &kp N3     &kp N4     &kp N5                     &kp N6            &kp N7     &kp N8   &kp N9  &kp N0     &kp MINUS
&kp TAB    &kp LA(P)      &kp LA(O)   &kp LA(I)  &kp LA(U)  &kp LA(Y)                  &none             &none      &none    &none   &none      &kp BSPC
&kp ESC    &kp SEMICOLON  &kp LA(L)   &kp LA(K)  &kp LA(J)  &kp LA(H)                  &none             &none      &none    &none   &kp LA(A)  &kp RET
&kp DEL    &none          &kp PERIOD  &kp COMMA  &kp LA(M)  &kp LA(N)  &none    &none  &none             &none      &none    &none   &none      &kp DEL
                                      &kp ESC    &kp TAB    &kp BSPC   &none    &none  &mt LSHIFT SPACE  &kp ENTER  &kp DEL
            >;
        };
    };

    conditional_layers { compatible = "zmk,conditional-layers"; };
};
